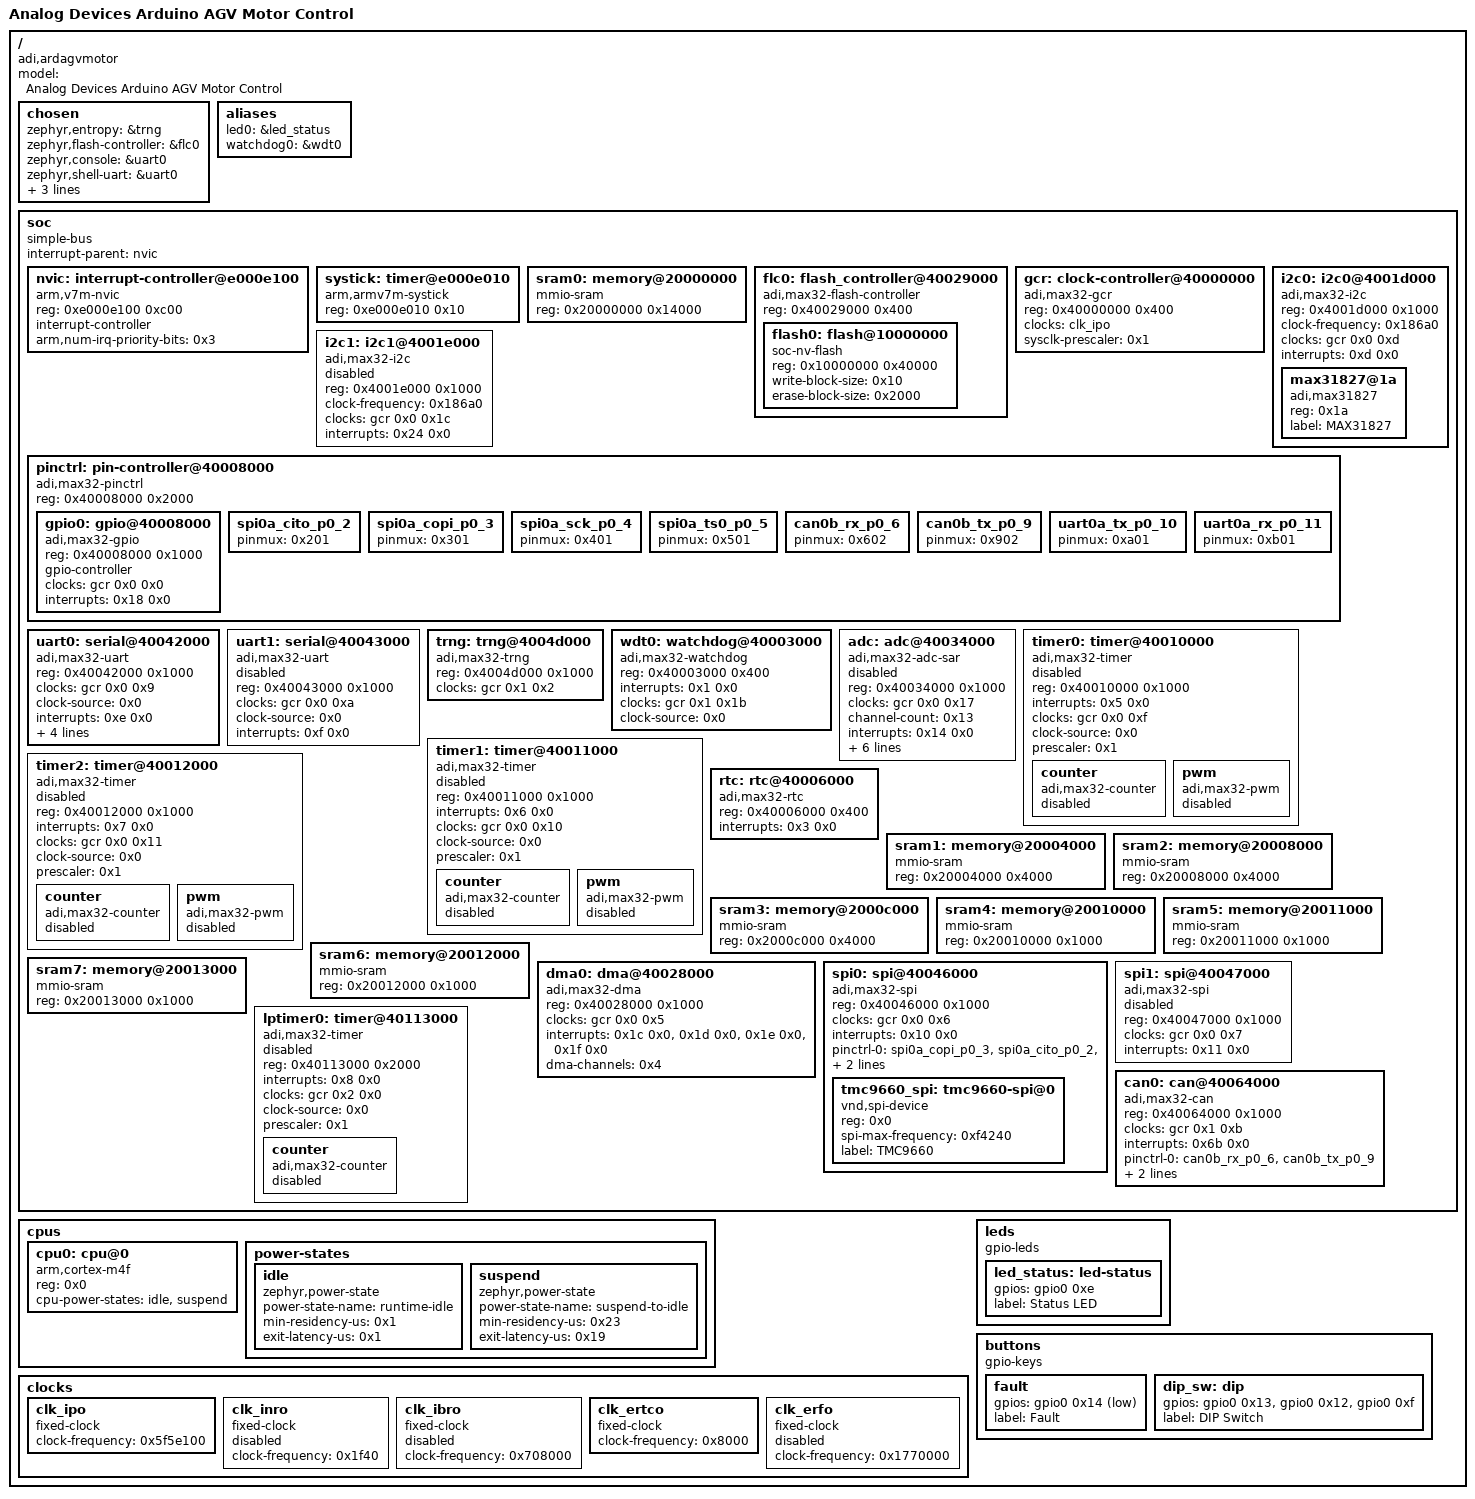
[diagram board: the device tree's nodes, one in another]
/dts-v1/;

/ {
	#address-cells = < 0x1 >;
	#size-cells = < 0x1 >;
	model = "Analog Devices Arduino AGV Motor Control";
	compatible = "adi,ardagvmotor";
	chosen {
		zephyr,entropy = &trng;
		zephyr,flash-controller = &flc0;
		zephyr,console = &uart0;
		zephyr,shell-uart = &uart0;
		zephyr,sram = &sram2;
		zephyr,flash = &flash0;
		zephyr,canbus = &can0;
	};
	aliases {
		led0 = &led_status;
		watchdog0 = &wdt0;
	};
	soc {
		#address-cells = < 0x1 >;
		#size-cells = < 0x1 >;
		compatible = "simple-bus";
		interrupt-parent = < &nvic >;
		ranges;
		nvic: interrupt-controller@e000e100 {
			#address-cells = < 0x1 >;
			compatible = "arm,v7m-nvic";
			reg = < 0xe000e100 0xc00 >;
			interrupt-controller;
			#interrupt-cells = < 0x2 >;
			arm,num-irq-priority-bits = < 0x3 >;
			phandle = < 0x1 >;
		};
		systick: timer@e000e010 {
			compatible = "arm,armv7m-systick";
			reg = < 0xe000e010 0x10 >;
		};
		sram0: memory@20000000 {
			compatible = "mmio-sram";
			reg = < 0x20000000 0x14000 >;
		};
		flc0: flash_controller@40029000 {
			compatible = "adi,max32-flash-controller";
			reg = < 0x40029000 0x400 >;
			#address-cells = < 0x1 >;
			#size-cells = < 0x1 >;
			status = "okay";
			flash0: flash@10000000 {
				compatible = "soc-nv-flash";
				reg = < 0x10000000 0x40000 >;
				write-block-size = < 0x10 >;
				erase-block-size = < 0x2000 >;
			};
		};
		gcr: clock-controller@40000000 {
			reg = < 0x40000000 0x400 >;
			compatible = "adi,max32-gcr";
			#clock-cells = < 0x2 >;
			clocks = < &clk_ipo >;
			sysclk-prescaler = < 0x1 >;
			status = "okay";
			phandle = < 0x3 >;
		};
		i2c0: i2c0@4001d000 {
			compatible = "adi,max32-i2c";
			reg = < 0x4001d000 0x1000 >;
			#address-cells = < 0x1 >;
			#size-cells = < 0x0 >;
			clock-frequency = < 0x186a0 >;
			clocks = < &gcr 0x0 0xd >;
			interrupts = < 0xd 0x0 >;
			status = "okay";
			max31827@1a {
				compatible = "adi,max31827";
				reg = < 0x1a >;
				label = "MAX31827";
				status = "okay";
			};
		};
		i2c1: i2c1@4001e000 {
			compatible = "adi,max32-i2c";
			reg = < 0x4001e000 0x1000 >;
			#address-cells = < 0x1 >;
			#size-cells = < 0x0 >;
			clock-frequency = < 0x186a0 >;
			clocks = < &gcr 0x0 0x1c >;
			interrupts = < 0x24 0x0 >;
			status = "disabled";
		};
		pinctrl: pin-controller@40008000 {
			compatible = "adi,max32-pinctrl";
			#address-cells = < 0x1 >;
			#size-cells = < 0x1 >;
			reg = < 0x40008000 0x2000 >;
			gpio0: gpio@40008000 {
				reg = < 0x40008000 0x1000 >;
				compatible = "adi,max32-gpio";
				gpio-controller;
				#gpio-cells = < 0x2 >;
				clocks = < &gcr 0x0 0x0 >;
				interrupts = < 0x18 0x0 >;
				status = "okay";
				phandle = < 0xa >;
			};
			spi0a_cito_p0_2: spi0a_cito_p0_2 {
				pinmux = < 0x201 >;
				phandle = < 0x7 >;
			};
			spi0a_copi_p0_3: spi0a_copi_p0_3 {
				pinmux = < 0x301 >;
				phandle = < 0x6 >;
			};
			spi0a_sck_p0_4: spi0a_sck_p0_4 {
				pinmux = < 0x401 >;
				phandle = < 0x8 >;
			};
			spi0a_ts0_p0_5: spi0a_ts0_p0_5 {
				pinmux = < 0x501 >;
				phandle = < 0x9 >;
			};
			can0b_rx_p0_6: can0b_rx_p0_6 {
				pinmux = < 0x602 >;
				phandle = < 0xb >;
			};
			can0b_tx_p0_9: can0b_tx_p0_9 {
				pinmux = < 0x902 >;
				phandle = < 0xc >;
			};
			uart0a_tx_p0_10: uart0a_tx_p0_10 {
				pinmux = < 0xa01 >;
				phandle = < 0x4 >;
			};
			uart0a_rx_p0_11: uart0a_rx_p0_11 {
				pinmux = < 0xb01 >;
				phandle = < 0x5 >;
			};
		};
		uart0: serial@40042000 {
			compatible = "adi,max32-uart";
			reg = < 0x40042000 0x1000 >;
			clocks = < &gcr 0x0 0x9 >;
			clock-source = < 0x0 >;
			interrupts = < 0xe 0x0 >;
			status = "okay";
			pinctrl-0 = < &uart0a_tx_p0_10 &uart0a_rx_p0_11 >;
			pinctrl-names = "default";
			current-speed = < 0x1c200 >;
			data-bits = < 0x8 >;
			parity = "none";
		};
		uart1: serial@40043000 {
			compatible = "adi,max32-uart";
			reg = < 0x40043000 0x1000 >;
			clocks = < &gcr 0x0 0xa >;
			clock-source = < 0x0 >;
			interrupts = < 0xf 0x0 >;
			status = "disabled";
		};
		trng: trng@4004d000 {
			compatible = "adi,max32-trng";
			reg = < 0x4004d000 0x1000 >;
			clocks = < &gcr 0x1 0x2 >;
			status = "okay";
		};
		wdt0: watchdog@40003000 {
			compatible = "adi,max32-watchdog";
			reg = < 0x40003000 0x400 >;
			interrupts = < 0x1 0x0 >;
			clocks = < &gcr 0x1 0x1b >;
			clock-source = < 0x0 >;
			status = "okay";
		};
		adc: adc@40034000 {
			compatible = "adi,max32-adc-sar", "adi,max32-adc";
			reg = < 0x40034000 0x1000 >;
			clocks = < &gcr 0x0 0x17 >;
			channel-count = < 0x13 >;
			#io-channel-cells = < 0x1 >;
			interrupts = < 0x14 0x0 >;
			resolution = < 0xc >;
			vref-mv = < 0x4e2 >;
			status = "disabled";
			clock-source = < 0x0 >;
			clock-divider = < 0x10 >;
			track-count = < 0x4 >;
			idle-count = < 0x0 >;
		};
		timer0: timer@40010000 {
			compatible = "adi,max32-timer";
			reg = < 0x40010000 0x1000 >;
			interrupts = < 0x5 0x0 >;
			status = "disabled";
			clocks = < &gcr 0x0 0xf >;
			clock-source = < 0x0 >;
			prescaler = < 0x1 >;
			counter {
				compatible = "adi,max32-counter";
				status = "disabled";
			};
			pwm {
				compatible = "adi,max32-pwm";
				status = "disabled";
				#pwm-cells = < 0x3 >;
			};
		};
		timer1: timer@40011000 {
			compatible = "adi,max32-timer";
			reg = < 0x40011000 0x1000 >;
			interrupts = < 0x6 0x0 >;
			status = "disabled";
			clocks = < &gcr 0x0 0x10 >;
			clock-source = < 0x0 >;
			prescaler = < 0x1 >;
			counter {
				compatible = "adi,max32-counter";
				status = "disabled";
			};
			pwm {
				compatible = "adi,max32-pwm";
				status = "disabled";
				#pwm-cells = < 0x3 >;
			};
		};
		timer2: timer@40012000 {
			compatible = "adi,max32-timer";
			reg = < 0x40012000 0x1000 >;
			interrupts = < 0x7 0x0 >;
			status = "disabled";
			clocks = < &gcr 0x0 0x11 >;
			clock-source = < 0x0 >;
			prescaler = < 0x1 >;
			counter {
				compatible = "adi,max32-counter";
				status = "disabled";
			};
			pwm {
				compatible = "adi,max32-pwm";
				status = "disabled";
				#pwm-cells = < 0x3 >;
			};
		};
		rtc: rtc@40006000 {
			compatible = "adi,max32-rtc";
			reg = < 0x40006000 0x400 >;
			interrupts = < 0x3 0x0 >;
			status = "okay";
		};
		sram1: memory@20004000 {
			compatible = "mmio-sram";
			reg = < 0x20004000 0x4000 >;
		};
		sram2: memory@20008000 {
			compatible = "mmio-sram";
			reg = < 0x20008000 0x4000 >;
		};
		sram3: memory@2000c000 {
			compatible = "mmio-sram";
			reg = < 0x2000c000 0x4000 >;
		};
		sram4: memory@20010000 {
			compatible = "mmio-sram";
			reg = < 0x20010000 0x1000 >;
		};
		sram5: memory@20011000 {
			compatible = "mmio-sram";
			reg = < 0x20011000 0x1000 >;
		};
		sram6: memory@20012000 {
			compatible = "mmio-sram";
			reg = < 0x20012000 0x1000 >;
		};
		sram7: memory@20013000 {
			compatible = "mmio-sram";
			reg = < 0x20013000 0x1000 >;
		};
		dma0: dma@40028000 {
			compatible = "adi,max32-dma";
			reg = < 0x40028000 0x1000 >;
			clocks = < &gcr 0x0 0x5 >;
			interrupts = < 0x1c 0x0 >, < 0x1d 0x0 >, < 0x1e 0x0 >, < 0x1f 0x0 >;
			dma-channels = < 0x4 >;
			status = "okay";
			#dma-cells = < 0x2 >;
		};
		spi0: spi@40046000 {
			compatible = "adi,max32-spi";
			reg = < 0x40046000 0x1000 >;
			#address-cells = < 0x1 >;
			#size-cells = < 0x0 >;
			clocks = < &gcr 0x0 0x6 >;
			interrupts = < 0x10 0x0 >;
			status = "okay";
			pinctrl-0 = < &spi0a_copi_p0_3 &spi0a_cito_p0_2 &spi0a_sck_p0_4 &spi0a_ts0_p0_5 >;
			pinctrl-names = "default";
			cs-gpios = < &gpio0 0x5 0x1 >;
			tmc9660_spi: tmc9660-spi@0 {
				compatible = "vnd,spi-device";
				reg = < 0x0 >;
				spi-max-frequency = < 0xf4240 >;
				label = "TMC9660";
				status = "okay";
			};
		};
		spi1: spi@40047000 {
			compatible = "adi,max32-spi";
			reg = < 0x40047000 0x1000 >;
			#address-cells = < 0x1 >;
			#size-cells = < 0x0 >;
			clocks = < &gcr 0x0 0x7 >;
			interrupts = < 0x11 0x0 >;
			status = "disabled";
		};
		lptimer0: timer@40113000 {
			compatible = "adi,max32-timer";
			reg = < 0x40113000 0x2000 >;
			interrupts = < 0x8 0x0 >;
			status = "disabled";
			clocks = < &gcr 0x2 0x0 >;
			clock-source = < 0x0 >;
			prescaler = < 0x1 >;
			counter {
				compatible = "adi,max32-counter";
				status = "disabled";
			};
		};
		can0: can@40064000 {
			compatible = "adi,max32-can";
			reg = < 0x40064000 0x1000 >;
			clocks = < &gcr 0x1 0xb >;
			interrupts = < 0x6b 0x0 >;
			status = "okay";
			pinctrl-0 = < &can0b_rx_p0_6 &can0b_tx_p0_9 >;
			pinctrl-names = "default";
			bitrate = < 0x7a120 >;
			sample-point = < 0x352 >;
		};
	};
	cpus {
		#address-cells = < 0x1 >;
		#size-cells = < 0x0 >;
		cpu0: cpu@0 {
			device_type = "cpu";
			compatible = "arm,cortex-m4f";
			reg = < 0x0 >;
			cpu-power-states = < &idle &suspend >;
		};
		power-states {
			idle: idle {
				compatible = "zephyr,power-state";
				power-state-name = "runtime-idle";
				min-residency-us = < 0x1 >;
				exit-latency-us = < 0x1 >;
				phandle = < 0xd >;
			};
			suspend: suspend {
				compatible = "zephyr,power-state";
				power-state-name = "suspend-to-idle";
				min-residency-us = < 0x23 >;
				exit-latency-us = < 0x19 >;
				phandle = < 0xe >;
			};
		};
	};
	clocks {
		clk_ipo: clk_ipo {
			compatible = "fixed-clock";
			#clock-cells = < 0x0 >;
			clock-frequency = < 0x5f5e100 >;
			status = "okay";
			phandle = < 0x2 >;
		};
		clk_inro: clk_inro {
			compatible = "fixed-clock";
			#clock-cells = < 0x0 >;
			clock-frequency = < 0x1f40 >;
			status = "disabled";
		};
		clk_ibro: clk_ibro {
			compatible = "fixed-clock";
			#clock-cells = < 0x0 >;
			clock-frequency = < 0x708000 >;
			status = "disabled";
		};
		clk_ertco: clk_ertco {
			compatible = "fixed-clock";
			#clock-cells = < 0x0 >;
			clock-frequency = < 0x8000 >;
			status = "okay";
		};
		clk_erfo: clk_erfo {
			compatible = "fixed-clock";
			#clock-cells = < 0x0 >;
			clock-frequency = < 0x1770000 >;
			status = "disabled";
		};
	};
	leds {
		compatible = "gpio-leds";
		status = "okay";
		led_status: led-status {
			gpios = < &gpio0 0xe 0x0 >;
			label = "Status LED";
			status = "okay";
		};
	};
	buttons {
		compatible = "gpio-keys";
		status = "okay";
		fault: fault {
			gpios = < &gpio0 0x14 0x1 >;
			label = "Fault";
			status = "okay";
		};
		dip_sw: dip {
			gpios = < &gpio0 0x13 0x0 >, < &gpio0 0x12 0x0 >, < &gpio0 0xf 0x0 >;
			label = "DIP Switch";
			status = "okay";
		};
	};
};
